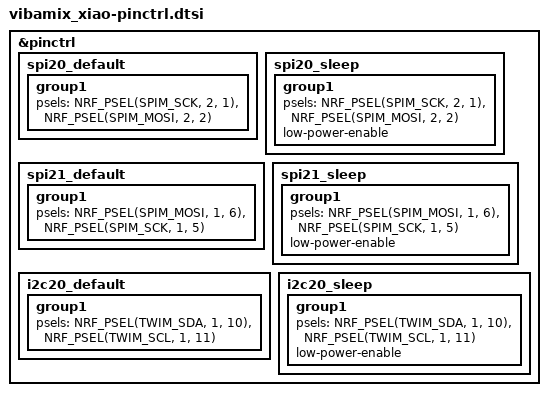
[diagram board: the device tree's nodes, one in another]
#include <dt-bindings/pinctrl/nrf-pinctrl.h>

&pinctrl {
	/* ePaper display SPI bus - MISO omitted, display is write-only */
	spi20_default: spi20_default {
		group1 {
			psels = <NRF_PSEL(SPIM_SCK,  2, 1)>,	/* P2.01 SPI_CLK  */
				<NRF_PSEL(SPIM_MOSI, 2, 2)>;	/* P2.02 SPI_MOSI */
		};
	};

	spi20_sleep: spi20_sleep {
		group1 {
			psels = <NRF_PSEL(SPIM_SCK,  2, 1)>,
				<NRF_PSEL(SPIM_MOSI, 2, 2)>;
			low-power-enable;
		};
	};

	/* WS2812 LED strip - SCK routed to NC P1.05, only MOSI (DIN) is wired */
	spi21_default: spi21_default {
		group1 {
			psels = <NRF_PSEL(SPIM_MOSI, 1, 6)>,	/* P1.06 LED_DIN  */
				<NRF_PSEL(SPIM_SCK,  1, 5)>;	/* P1.05 NC       */
		};
	};

	spi21_sleep: spi21_sleep {
		group1 {
			psels = <NRF_PSEL(SPIM_MOSI, 1, 6)>,
				<NRF_PSEL(SPIM_SCK,  1, 5)>;
			low-power-enable;
		};
	};

	/* Light sensor I2C bus */
	i2c20_default: i2c20_default {
		group1 {
			psels = <NRF_PSEL(TWIM_SDA, 1, 10)>,	/* P1.10 LIGHT_SENSOR_SDA */
				<NRF_PSEL(TWIM_SCL, 1, 11)>;	/* P1.11 LIGHT_SENSOR_SCL */
		};
	};

	i2c20_sleep: i2c20_sleep {
		group1 {
			psels = <NRF_PSEL(TWIM_SDA, 1, 10)>,
				<NRF_PSEL(TWIM_SCL, 1, 11)>;
			low-power-enable;
		};
	};
};
